# STM32H5F4xx register map
File version: 1.0
Registers are 32-bit, read-write, reset 0x0 unless marked. A register's access mark holds for its fields unless they carry their own. Offsets are from the block's base; [hi:lo] are bit positions; {n}, {i} and the like mark numbered series; 'fields as' and 'values as' point back to an identical list.

## DMA2D — DMA2D Controller
Base 0x4002A000
Same registers: DMA2D_S 0x5002A000
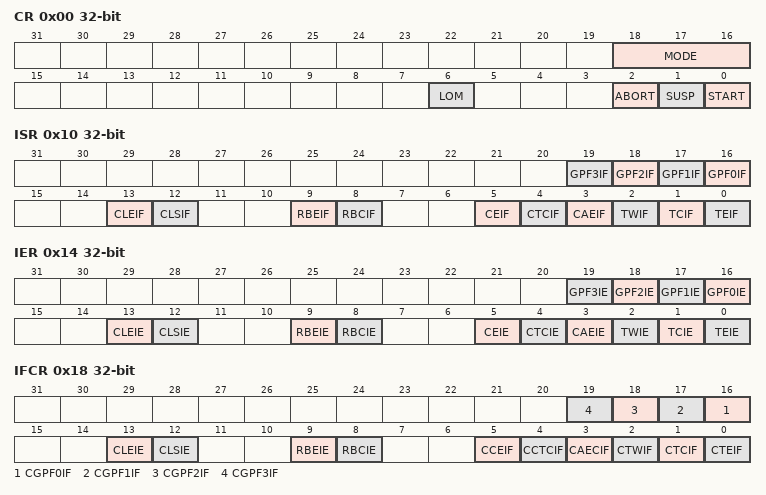
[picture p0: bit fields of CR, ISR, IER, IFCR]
0x00 CR — DMA2D control register
  [18:16] MODE — DMA2D Mode
    0=M2M (DMA2D memory to memory transfer mode); 1=M2M_PFC (DMA2D memory to memory with pixel format conversion transfer mode); 2=M2M_BLEND (DMA2D memory to memory with blending transfer mode); 3=R2M (DMA2D register to memory transfer mode); 4=M2M_BLEND_FIXED_COLOR_FG (DMA2D memory to memory with blending transfer mode and fixed color foreground); 5=M2M_BLEND_FIXED_COLOR_BG (DMA2D memory to memory with blending transfer mode and fixed color background)
  [6] LOM — Line offset mode
    0=PIXELS (Line offsets are expressed in pixels); 1=BYTES (Line offsets are expressed in bytes)
  [2] ABORT — Abort transfer
  [1] SUSP — Suspend transfer
  [0] START — Start transfer
0x10 ISR — DMA2D interrupt status register
  [n+16] GPF{n}IF (n=0..3) — General Purpose Flag {n} Interrupt Flag
  [13] CLEIF — CLUT Loading Error Interrupt Flag
  [12] CLSIF — CLUT Loading Suspend Interrupt Flag
  [9] RBEIF — Read Bus Error Interrupt Flag
  [8] RBCIF — Read Bus Error Interrupt Flag
  [5] CEIF — Configuration Error Interrupt Flag
  [4] CTCIF — CLUT Transfer Complete Interrupt Flag
  [3] CAEIF — CLUT Access Error Interrupt Flag
  [2] TWIF — Transfer Watermark Interrupt Flag
  [1] TCIF — Transfer Complete Interrupt Flag
  [0] TEIF — Transfer Error Interrupt Flag
0x14 IER — DMA2D interrupt enable register
  [n+16] GPF{n}IE (n=0..3) — General Purpose Flag {n} Interrupt Enable
  [13] CLEIE — Configuration Error Interrupt Enable
  [12] CLSIE — Configuration Error Interrupt Enable
  [9] RBEIE — Configuration Error Interrupt Enable
  [8] RBCIE — Configuration Error Interrupt Enable
  [5] CEIE — Configuration Error Interrupt Enable
  [4] CTCIE — CLUT Transfer Complete Interrupt Enable
  [3] CAEIE — CLUT Access Error Interrupt Enable
  [2] TWIE — Transfer Watermark Interrupt Enable
  [1] TCIE — Transfer Complete Interrupt Enable
  [0] TEIE — Transfer Error Interrupt Enable
0x18 IFCR — DMA2D interrupt flag clear register
  [n+16] CGPF{n}IF (n=0..3) — Clears General Purpose Flag {n} Interrupt Flag
  [13] CLEIE — Clears Configuration Error Interrupt Enable
  [12] CLSIE — Clears Configuration Error Interrupt Enable
  [9] RBEIE — Clears Configuration Error Interrupt Enable
  [8] RBCIE — Clears Configuration Error Interrupt Enable
  [5] CCEIF — Clears Configuration Error Interrupt Flag
  [4] CCTCIF — Clears CLUT Transfer Complete Interrupt Flag
  [3] CAECIF — Clears CLUT Access Error Interrupt Flag
  [2] CTWIF — Clears Transfer Watermark Interrupt Flag
  [1] CTCIF — Clears Transfer Complete Interrupt Flag
  [0] CTEIF — Clears Transfer Error Interrupt Flag
0x40 FGMAR — DMA2D foreground memory address register
  [31:0] MA — Foreground Memory Address
0x44 FGOR — DMA2D foreground
  [15:0] LO — Line Offset
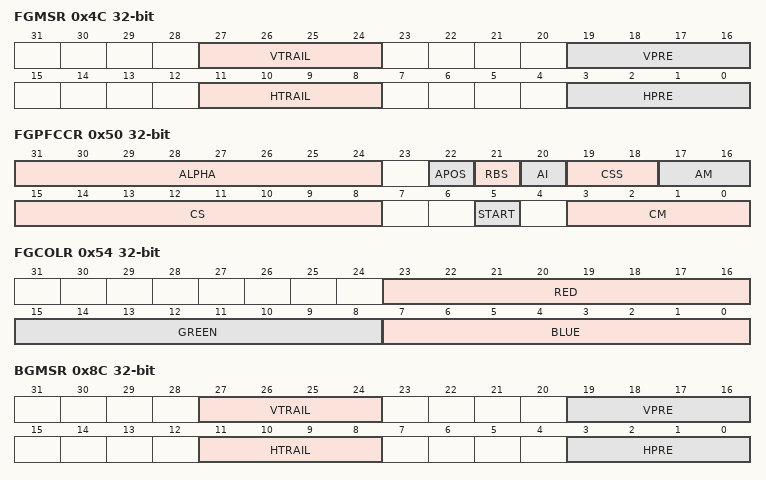
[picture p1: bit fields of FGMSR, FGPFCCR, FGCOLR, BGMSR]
0x4C FGMSR — DMA2D foreground memory skip register
  [27:24] VTRAIL — Line Offset
  [19:16] VPRE — Line Offset
  [11:8] HTRAIL — Line Offset
  [3:0] HPRE — Line Offset
0x50 FGPFCCR — DMA2D foreground PFC control register
  [31:24] ALPHA — Alpha value
  [22] APOS — Alpha Inverted Position
  [21] RBS — Foreground Input Red Blue Swap
    0=REGULAR (RGB or ARGB); 1=SWAP (BGR or ABGR)
  [20] AI — Foreground Input Alpha Inverted
    0=REGULAR (Regular alpha); 1=INVERTED (Inverted alpha)
  [19:18] CSS — Chroma Sub-Sampling
    0=No chroma sub-sampling 4:4:4; 1=chroma sub-sampling 4:2:2; 2=chroma sub-sampling 4:2:0
  [17:16] AM — Alpha mode AM[1:0]
    0=NO_MODIF (No modification of the alpha channel value); 1=REPLACE; 2=COMBINE
  [15:8] CS — CLUT size
  [5] START
  [3:0] CM — Input color mode CM[3:0]
    0=ARGB8888; 1=RGB888; 2=RGB565; 3=ARGB1555; 4=ARGB4444; 5=L8; 6=AL44; 7=AL88; 8=L4; 9=A8; 10=A4; 14=ARGB2222
0x54 FGCOLR — DMA2D foreground color register
  [23:16] RED — Foreground Red Value
  [15:8] GREEN — Foreground Green Value
  [7:0] BLUE — Foreground Blue Value
0x58 FGCMAR — DMA2D foreground CLUT memory address register
  [31:0] MA — Foreground CLUT Memory Address
0x80 BGMAR — DMA2D background memory address register
  [31:0] MA — Background Memory Address
0x84 BGOR — DMA2D background
  [15:0] LO — Line Offset
0x8C BGMSR — DMA2D background memory skip register
  fields as FGMSR
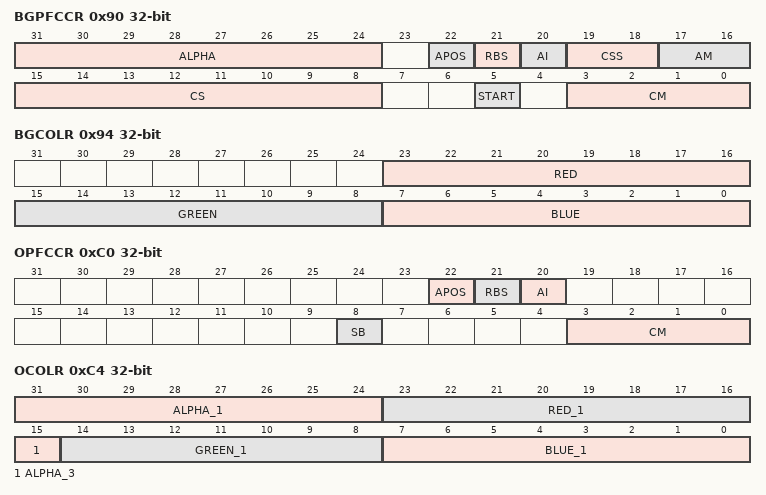
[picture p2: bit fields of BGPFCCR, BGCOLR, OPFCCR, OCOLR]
0x90 BGPFCCR — DMA2D background PFC control register
  [31:24] ALPHA — background Input Alpha value
  [22] APOS — Alpha position
  [21] RBS — Background Input Red Blue Swap
    0=REGULAR (RGB or ARGB); 1=SWAP (BGR or ABGR)
  [20] AI — background Input Alpha Inverted
    0=REGULAR (Regular alpha); 1=INVERTED (Inverted alpha)
  [19:18] CSS — Chroma sub-sampling
  [17:16] AM — Alpha mode AM[1:0]
    values as FGPFCCR.AM
  [15:8] CS — CLUT size
  [5] START
  [3:0] CM — Input color mode CM[3:0]
    0=ARGB8888; 1=RGB888; 2=RGB565; 3=ARGB1555; 4=ARGB4444; 5=L8; 6=AL44; 7=AL88; 8=L4; 9=A8; 10=A4
0x94 BGCOLR — DMA2D background color register
  [23:16] RED — Background Red Value
  [15:8] GREEN — Background Green Value
  [7:0] BLUE — Background Blue Value
0x98 BGCMAR — DMA2D background CLUT memory address register
  [31:0] MA — Background CLUT Memory Address
0xC0 OPFCCR — DMA2D output PFC control register
  [22] APOS — Alpha Position
  [21] RBS — Output Red Blue Swap
    0=REGULAR (RGB or ARGB); 1=SWAP (BGR or ABGR)
  [20] AI — Output Alpha Inverted
    0=REGULAR (Regular alpha); 1=INVERTED (Inverted alpha)
  [8] SB — Swap Bytes
    0=REGULAR (Regular order); 1=TWO_BY_TWO (Bytes swapped two by two)
  [3:0] CM — Output Color mode CM[3:0]
    0=ARGB8888; 1=RGB888; 2=RGB565; 3=ARGB1555; 4=ARGB4444
0xC4 OCOLR — DMA2D output color register
  [31:24] ALPHA_1 — Output Alpha Channel Value
  [23:16] RED_1 — Output Red Value
  [15] ALPHA_3 — Output Alpha Channel Value
  [14:8] GREEN_1 — Output GREEN Value
  [7:0] BLUE_1 — Output BLUE Value
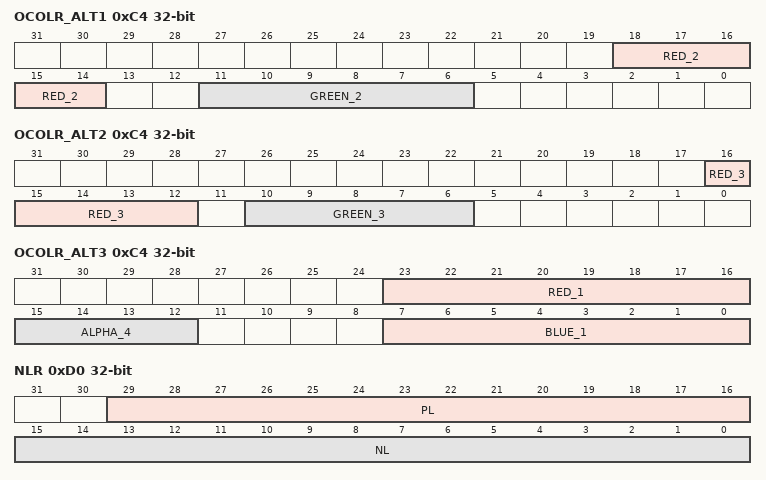
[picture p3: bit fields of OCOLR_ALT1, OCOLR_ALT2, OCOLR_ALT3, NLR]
0xC4 OCOLR_ALT1 (alternate view of OCOLR) — DMA2D output color register
  [18:14] RED_2 — Output Red Value
  [11:6] GREEN_2 — Output GREEN Value
0xC4 OCOLR_ALT2 (alternate view of OCOLR) — DMA2D output color register
  [16:12] RED_3 — Output Red Value
  [10:6] GREEN_3 — Output GREEN Value
0xC4 OCOLR_ALT3 (alternate view of OCOLR) — DMA2D output color register
  [23:16] RED_1 — Output Red Value
  [15:12] ALPHA_4 — Output Alpha Channel Value
  [7:0] BLUE_1 — Output BLUE Value
0xC8 OMAR — DMA2D output memory address register
  [31:0] MA — Output Memory Address
0xCC OOR — DMA2D output
  [15:0] LO — Output Line Offset
0xD0 NLR — DMA2D number of line register
  [29:16] PL — Pixel per Lines
  [15:0] NL — Number of Lines
0xE0 LWR — DMA2D line watermark register
  [15:0] LW — Line Watermark
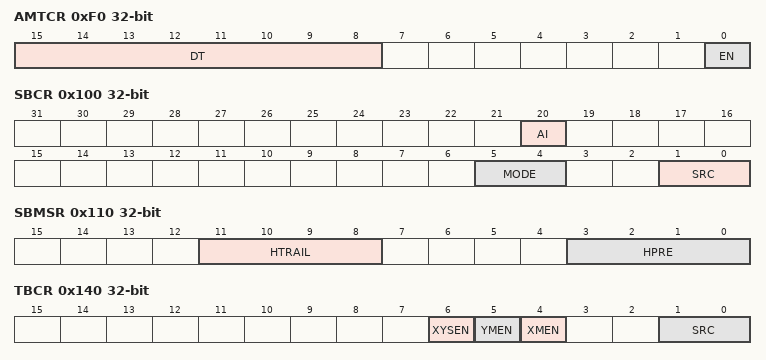
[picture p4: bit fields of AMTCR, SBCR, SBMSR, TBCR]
0xF0 AMTCR — DMA2D AHB master timer configuration register
  [15:8] DT — Dead Time
  [0] EN — Enable
0x100 SBCR — DMA2D stencil buffer configuration register
  [20] AI — Alpha Inverted
  [5:4] MODE
  [1:0] SRC — Source
0x104 SBMAR — DMA2D stencil buffer memory address register
  [31:0] MA — Memory address, address of the data used for the stencil buffer
0x108 SBOR — DMA2D stencil buffer
  [15:0] LO — Line offset
0x110 SBMSR — DMA2D stencil buffer memory skip register
  [11:8] HTRAIL — Horizontal trailing pixels
  [3:0] HPRE — Horizontal pre pixels
0x140 TBCR — DMA2D tile buffer configuration register
  [6] XYSEN — X/Y swap enable
  [5] YMEN — Y mirroring enable
  [4] XMEN — X mirroring enable
  [1:0] SRC — Source
0x180 SCR — DMA2D scaler configuration register
  [1:0] SRC — Source
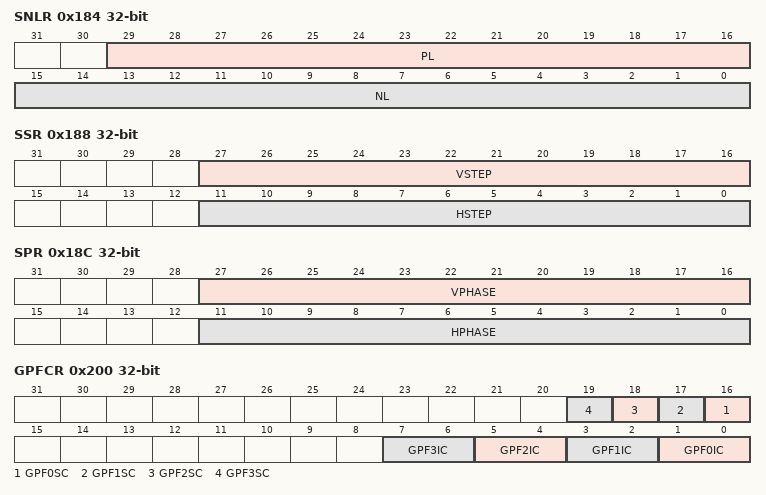
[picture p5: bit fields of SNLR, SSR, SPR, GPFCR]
0x184 SNLR — DMA2D scaler number of line register
  [29:16] PL — Pixel per lines
  [15:0] NL — Number of lines
0x188 SSR — DMA2D scaler step register
  [27:16] VSTEP — vertical step
  [11:0] HSTEP — horizontal step
0x18C SPR — DMA2D scaler phase register
  [27:16] VPHASE — vertical phase
  [11:0] HPHASE — horizontal phase
0x200 GPFCR — DMA2D general purpose flag configuration register
  [n+16] GPF{n}SC (n=0..3) — General purpose flag {n} suspend configuration
  [2n+1:2n] GPF{n}IC (n=0..3) — General purpose flag {n} interrupt configuration
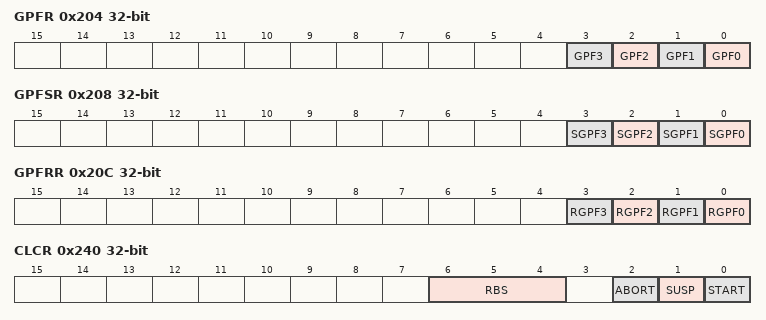
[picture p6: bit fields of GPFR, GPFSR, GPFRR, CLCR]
0x204 GPFR — DMA2D general purpose flag register
  [n] GPF{n} (n=0..3) — General purpose flag {n}
0x208 GPFSR — DMA2D general purpose flag set register
  [n] SGPF{n} (n=0..3) — Set general purpose flag {n}
0x20C GPFRR — DMA2D general purpose flag reset register
  [n] RGPF{n} (n=0..3) — Reset general purpose flag {n}
0x240 CLCR — DMA2D command list configuration register
  [6:4] RBS — Ring buffer size
  [2] ABORT
  [1] SUSP — Suspend
  [0] START
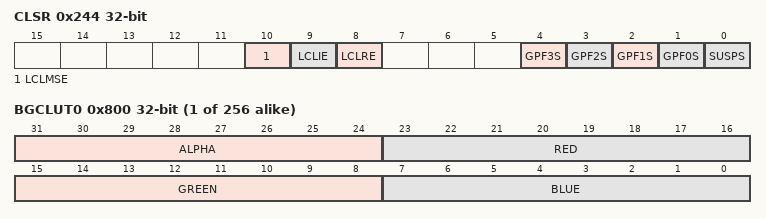
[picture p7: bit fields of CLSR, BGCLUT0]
0x244 CLSR — DMA2D command list status register
  [10] LCLMSE — Linear command list multiple start error
  [9] LCLIE — Linear command list instruction error
  [8] LCLRE — Linear command list read error
  [n+1] GPF{n}S (n=0..3) — General purpose flag {n} suspend
  [0] SUSPS — SUSP bit suspend
0x250 RBBAR — DMA2D ring buffer base address register
  [31:0] ADDRESS
0x254 RBHPR — DMA2D ring buffer head pointer register
  [13:0] HP — Head Pointer
0x258 RBWPR — DMA2D ring buffer write pointer register
  [13:0] WP — Write Pointer
0x260 LBCBAR — DMA2D linear buffer current base address register
  [31:0] ADDRESS
0x264 LBCSR — DMA2D linear buffer current size register
  [11:0] SIZE
0x268 LBCAR — DMA2D linear buffer current address register
  [31:0] ADDRESS
0x3F4 VERR — DMA2D version register
0x3F8 IPIDR — DMA2D identification register
  [31:0] ID — DMA2D identification code
0x3FC SIDR — DMA2D size identification register
  [31:0] SID — DMA2D size identification
{0x400+4i} FGCLUT[{i}] (i=0..255)
{0x800+4i} BGCLUT{i} (i=0..255) — DMA2D background CLUT
  [31:24] ALPHA, [23:16] RED, [15:8] GREEN, [7:0] BLUE
